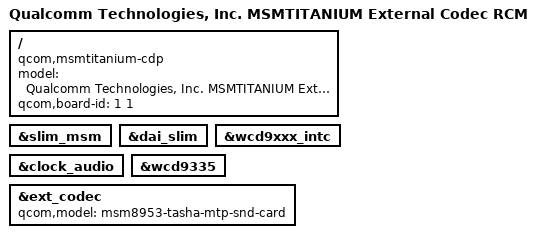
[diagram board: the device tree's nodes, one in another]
/*
 * Copyright (c) 2015, The Linux Foundation. All rights reserved.
 *
 * This program is free software; you can redistribute it and/or modify
 * it under the terms of the GNU General Public License version 2 and
 * only version 2 as published by the Free Software Foundation.
 *
 * This program is distributed in the hope that it will be useful,
 * but WITHOUT ANY WARRANTY; without even the implied warranty of
 * MERCHANTABILITY or FITNESS FOR A PARTICULAR PURPOSE.  See the
 * GNU General Public License for more details.
 */

/dts-v1/;

#include "msmtitanium.dtsi"
#include "msmtitanium-cdp.dtsi"

/ {
	model = "Qualcomm Technologies, Inc. MSMTITANIUM External Codec RCM";
	compatible = "qcom,msmtitanium-cdp", "qcom,msmtitanium", "qcom,cdp";
	qcom,board-id= <1 1>;
};

&slim_msm {
	status = "okay";
};

&dai_slim {
	status = "okay";
};

&wcd9xxx_intc {
	status = "okay";
};

&clock_audio {
	status = "okay";
};

&wcd9335 {
	status = "okay";
};

&ext_codec {
	qcom,model = "msm8953-tasha-mtp-snd-card";
	status = "okay";
};
